# RE01_1500KB register map
Vendor: Renesas Electronics Corporation; Series: RE01_1500KB; File version: 1.20
CPU: CM0PLUS r0p1, little endian, MPU, no FPU, VTOR, 2 interrupt priority bits
Registers are 8-bit, read-write, reset 0x0 unless marked. A register's access mark holds for its fields unless they carry their own. Offsets are from the block's base; [hi:lo] are bit positions; {n}, {i} and the like mark numbered series.

## IWDT — Independent Watchdog Timer
Base 0x40044400
0x00 IWDTRR reset 0xFF — IWDT Refresh Register
  [7:0] IWDTRR — The counter is refreshed by writing 0x00 and then writing 0xFF to this register.
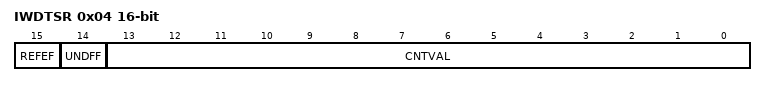
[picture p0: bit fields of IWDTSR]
0x04 IWDTSR 16-bit — IWDT Status Register
  [15] REFEF — Refresh Error Flag
    0=Refresh error not occurred; 1=Refresh error occurred
  [14] UNDFF — Underflow Flag
    0=Underflow not occurred; 1=Underflow occurred
  [13:0] CNTVAL ro — Counter ValueValue counted by the counter

## IrDA — Infrared Data Association Interface
Base 0x40070F00
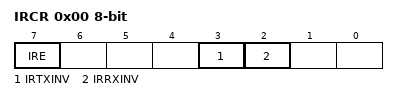
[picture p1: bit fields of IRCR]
0x00 IRCR — IrDA Control Resister
  [7] IRE, [3] IRTXINV, [2] IRRXINV

## KINT — Key Interrupt Function
Base 0x40080000
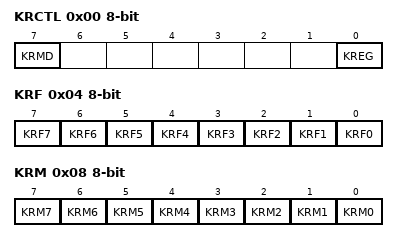
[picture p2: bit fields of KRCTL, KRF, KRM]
0x00 KRCTL — KEY Return Control Register
  [7] KRMD — Usage of Key Interrupt Flags(KR0 to KR7)
    0=Do not use key interrupt flags; 1=Use key interrupt flags
  [0] KREG — Detection Edge Selection (KRF0 to KRF7)
    0=Falling edge; 1=Rising edge
0x04 KRF — KEY Return Flag Register
  [all] fields
    0=No interrupt detected; 1=Interrupt detected
  [n] KRF{n} (n=0..7) — Key interrupt flag {n}
0x08 KRM — KEY Return Mode Register
  [all] fields
    0=Does not detect key interrupt signal; 1=Detect key interrupt signal
  [n] KRM{n} (n=0..7) — Key interrupt mode control {n}

## LED — LED Controler
Base 0x40086900
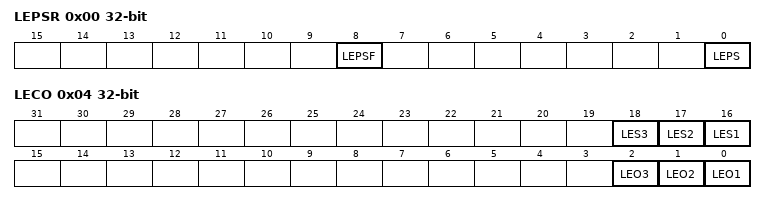
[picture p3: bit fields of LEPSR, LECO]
0x00 LEPSR 32-bit
  [8] LEPSF
    0=0; 1=:-
  [0] LEPS
    0=0; 1=:-
0x04 LECO 32-bit
  [all] fields
    0=0; 1=:-
  [18] LES3
  [17] LES2
  [16] LES1
  [2] LEO3
  [1] LEO2
  [0] LEO1
0x08 LEDWTCR 32-bit reset 0xC80
  [13:0] LESTS

## LPG — Low Speed Pulse Generator
Base 0x40084600; alternate view of DIV
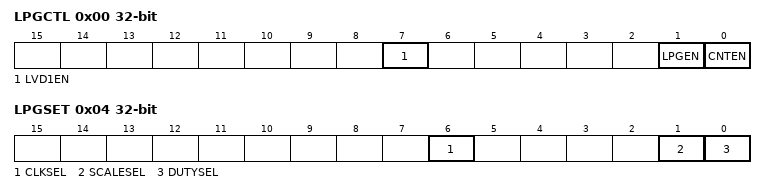
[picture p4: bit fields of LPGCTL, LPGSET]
0x00 LPGCTL 32-bit — Low Speed Pulse Generator Control Resister
  [7] LVD1EN, [1] LPGEN, [0] CNTEN
0x04 LPGSET 32-bit — Low Speed Pulse Generator Setting Resister
  [6] CLKSEL, [1] SCALESEL, [0] DUTYSEL

## LST — Low Speed Clock Timer
Base 0x40084400
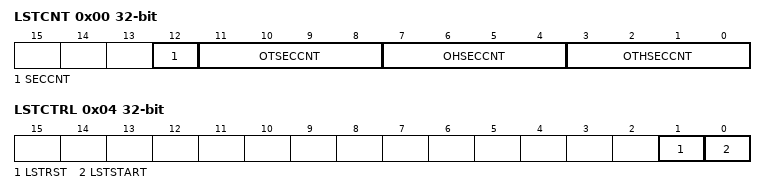
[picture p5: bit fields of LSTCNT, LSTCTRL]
0x00 LSTCNT 32-bit — Low Speed Clock Timer Count Resister
  [12] SECCNT ro, [11:8] OTSECCNT ro, [7:4] OHSECCNT ro, [3:0] OTHSECCNT ro
0x04 LSTCTRL 32-bit — Low Speed Clock Timer Control Resister
  [1] LSTRST, [0] LSTSTART

## MLCD — MLCD liquid crystal controler
Base 0x40070200
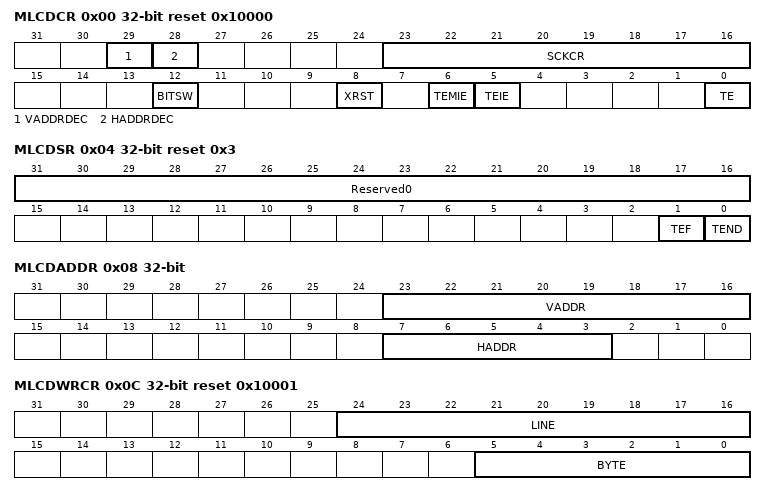
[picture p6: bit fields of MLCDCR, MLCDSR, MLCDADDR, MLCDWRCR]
0x00 MLCDCR 32-bit reset 0x10000 — MLCD Control Register
  [29] VADDRDEC, [28] HADDRDEC, [23:16] SCKCR, [12] BITSW, [8] XRST, [6] TEMIE, [5] TEIE wo, [0] TE
0x04 MLCDSR 32-bit reset 0x3 — MLCD Status Register
  [31:16] Reserved0 — These bits are read as 0. The write value should be 0.
  [1] TEF ro
  [0] TEND ro
0x08 MLCDADDR 32-bit — MLCD Address Setting Register
  [23:16] VADDR, [7:3] HADDR
0x0C MLCDWRCR 32-bit reset 0x10001 — MLCD Send data size setting register
  [24:16] LINE, [5:0] BYTE
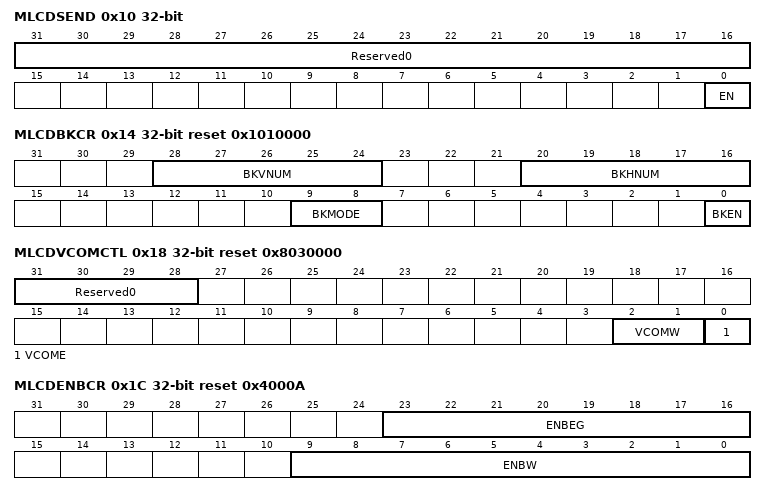
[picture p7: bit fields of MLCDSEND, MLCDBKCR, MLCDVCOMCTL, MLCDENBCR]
0x10 MLCDSEND 32-bit — MLCD Send data size setting register
  [31:16] Reserved0 — These bits are read as 0. The write value should be 0.
  [0] EN wo
0x14 MLCDBKCR 32-bit reset 0x1010000 — MLCD Block Transfer Setting Register
  [28:24] BKVNUM
  [20:16] BKHNUM
  [9:8] BKMODE
    0=00; 1=01; 2=10; 3=11
  [0] BKEN
0x18 MLCDVCOMCTL 32-bit reset 0x8030000 — MLCD VCOM Control Register
  [31:28] Reserved0 — These bits are read as 0. The write value should be 0.
  [2:1] VCOMW
    0=00; 1=01; 2=10; 3=11
  [0] VCOME
0x1C MLCDENBCR 32-bit reset 0x4000A — MLCD Enable Signal Control Register
  [23:16] ENBEG, [9:0] ENBW
{0x20+i} DATA{i} (i=0..31) — MLCD Enable Signal Control Register
  [7:0] DATA
{0x20+2i} DATA_HW{i} (i=0..15) 16-bit — MLCD Enable Signal Control Register(16bit)
{0x20+4i} DATA_W{i} (i=0..7) 32-bit — MLCD Enable Signal Control Register(32bit)
